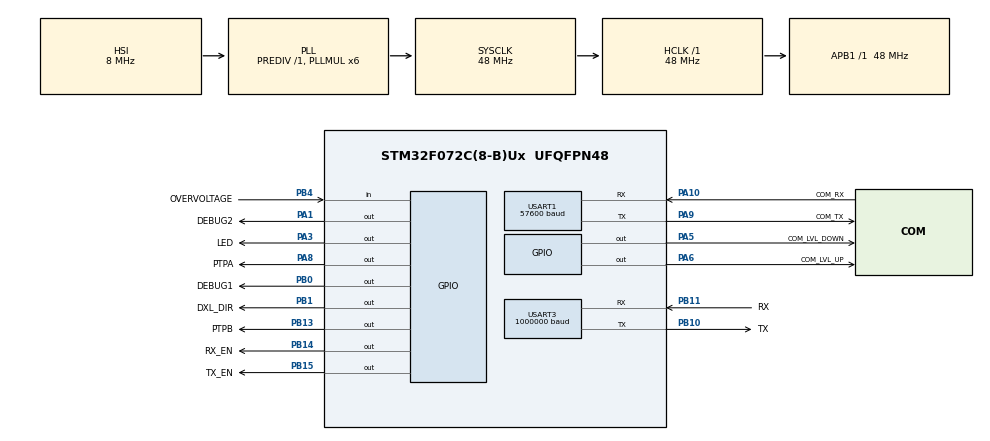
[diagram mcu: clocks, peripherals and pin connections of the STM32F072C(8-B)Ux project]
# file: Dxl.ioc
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Mcu.Family=STM32F0
Dma.USART3_RX.0.PeriphInc=DMA_PINC_DISABLE
PB13.Stacked=true
PB10.Mode=Asynchronous
PA10.GPIO_PuPd=GPIO_PULLUP
USART1.BaudRate=57600
PB14.GPIO_Label=RX_EN
VP_RTC_VS_RTC_Activate.Mode=RTC_Enabled
PA6.GPIO_Label=COM_LVL_UP
PB0.GPIO_Label=DEBUG1
PB13.GPIO_Label=PTPB
PB11.Signal=USART3_RX
PB13.Signal=SharedStack_PB13
PB15.Signal=GPIO_Output
PA5.PinState=GPIO_PIN_RESET
RCC.SYSCLKSource=RCC_SYSCLKSOURCE_PLLCLK
ProjectManager.StackSize=0x400
USART3.VirtualMode-Asynchronous=VM_ASYNC
SH.SharedStack_PB13.0=GPIO_Output+0
SH.SharedStack_PB13.1=GPIO_EXTI13
USART3.BaudRate=1000000
NVIC.USART3_4_IRQn=true\:2\:0\:true\:false\:true\:true\:true
RCC.HCLKFreq_Value=48000000
RCC.AHBFreq_Value=48000000
Dma.USART3_RX.0.MemDataAlignment=DMA_MDATAALIGN_BYTE
RCC.PLLMUL=RCC_PLL_MUL6
PA6.GPIO_PuPd=GPIO_PULLDOWN
PA5.GPIO_PuPd=GPIO_PULLUP
PB1.GPIO_Label=DXL_DIR
PA10.GPIO_Label=COM_RX
Dma.USART3_RX.0.PeriphDataAlignment=DMA_PDATAALIGN_BYTE
PA8.Signal=SharedStack_PA8
Dma.USART3_RX.0.Direction=DMA_PERIPH_TO_MEMORY
Mcu.Package=UFQFPN48
PB1.Signal=GPIO_Output
PA6.Signal=GPIO_Output
PA8.GPIO_ModeDefaultEXTI=GPIO_MODE_IT_FALLING
PA2.GPIO_Label=POWER_SENSOR
PA10.Signal=USART1_RX
Dma.USART3_RX.0.MemInc=DMA_MINC_ENABLE
RCC.APB1TimFreq_Value=48000000
SH.SharedStack_PA8.1=GPIO_EXTI8
NVIC.USART1_IRQn=true\:1\:0\:true\:false\:false\:true\:true
SH.SharedStack_PA8.0=GPIO_Output+0
Dma.Request0=USART3_RX
NVIC.EXTI4_15_IRQn=true\:0\:0\:false\:false\:true\:true\:true
PB4.Signal=GPIO_Input
PA3.Signal=GPIO_Output
Dma.USART3_RX.0.Instance=DMA1_Channel6
PA10.Mode=Asynchronous
PA9.GPIO_Label=COM_TX
PB11.GPIO_Label=RX
PA8.Stacked=true
PA6.PinState=GPIO_PIN_SET
PA9.GPIO_PuPd=GPIO_PULLUP
PB13.GPIO_ModeDefaultEXTI=GPIO_MODE_IT_FALLING
Dma.USART3_RX.0.Mode=DMA_NORMAL
USART1.VirtualMode-Asynchronous=VM_ASYNC
PA9.Mode=Asynchronous
PA8.GPIO_Label=PTPA
PB11.Mode=Asynchronous
ProjectManager.TargetToolchain=Other Toolchains (GPDSC)
PB10.GPIO_Label=TX
PA9.Signal=USART1_TX
PA1.Signal=GPIO_Output
PB10.Signal=USART3_TX
PB14.Signal=GPIO_Output
PA5.Signal=GPIO_Output
board=custom
PB13.GPIO_PuPd=GPIO_PULLUP
PB4.GPIO_Label=OVERVOLTAGE
NVIC.DMA1_Channel4_5_6_7_IRQn=true\:0\:0\:false\:false\:true\:false\:true
PB15.GPIO_Label=TX_EN
PA1.GPIO_Label=DEBUG2
Mcu.Name=STM32F072C(8-B)Ux
PA2.Signal=ADC_IN2
RCC.SYSCLKFreq_VALUE=48000000
Dma.USART3_RX.0.Priority=DMA_PRIORITY_LOW
PA5.GPIO_Label=COM_LVL_DOWN
ProjectManager.HeapSize=0x200
PA8.GPIO_PuPd=GPIO_PULLUP
RCC.APB1Freq_Value=48000000
PB0.Signal=GPIO_Output
PA3.GPIO_Label=LED

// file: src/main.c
/* USER CODE BEGIN Header */
/**
 ******************************************************************************
 * @file           : main.c
 * @brief          : Main program body
 ******************************************************************************
 * @attention
 *
 * <h2><center>&copy; Copyright (c) 2020 STMicroelectronics.
 * All rights reserved.</center></h2>
 *
 * This software component is licensed by ST under BSD 3-Clause license,
 * the "License"; You may not use this file except in compliance with the
 * License. You may obtain a copy of the License at:
 *                        opensource.org/licenses/BSD-3-Clause
 *
 ******************************************************************************
 */
/* USER CODE END Header */

#include "main.h"
#include "dma.h"
#include "rtc.h"
#include "usart.h"
#include "gpio.h"

/* USER CODE BEGIN Includes */
#include "luos_engine.h"
#include "robus_network.h"
#include "dxl.h"
/* USER CODE END Includes */

void SystemClock_Config(void);

int main(void)
{

    /* MCU Configuration--------------------------------------------------------*/

    /* Reset of all peripherals, Initializes the Flash interface and the Systick. */
    HAL_Init();

    /* Configure the system clock */
    SystemClock_Config();

    /* Initialize all configured peripherals */
    MX_GPIO_Init();
    MX_DMA_Init();
    MX_USART1_UART_Init();
    MX_USART3_UART_Init();
    MX_RTC_Init();
    /* USER CODE BEGIN 2 */
    Luos_Init();
    Robus_Init();
    Dxl_Init();
    /* USER CODE END 2 */

    /* Infinite loop */
    /* USER CODE BEGIN WHILE */
    while (1)
    {
        Luos_Loop();
        Dxl_Loop();
        /* USER CODE END WHILE */

    }
}

void SystemClock_Config(void)
{
    RCC_OscInitTypeDef RCC_OscInitStruct   = {0};
    RCC_ClkInitTypeDef RCC_ClkInitStruct   = {0};
    RCC_PeriphCLKInitTypeDef PeriphClkInit = {0};

    /** Initializes the CPU, AHB and APB busses clocks
     */
    RCC_OscInitStruct.OscillatorType      = RCC_OSCILLATORTYPE_HSI | RCC_OSCILLATORTYPE_LSI;
    RCC_OscInitStruct.HSIState            = RCC_HSI_ON;
    RCC_OscInitStruct.HSICalibrationValue = RCC_HSICALIBRATION_DEFAULT;
    RCC_OscInitStruct.LSIState            = RCC_LSI_ON;
    RCC_OscInitStruct.PLL.PLLState        = RCC_PLL_ON;
    RCC_OscInitStruct.PLL.PLLSource       = RCC_PLLSOURCE_HSI;
    RCC_OscInitStruct.PLL.PLLMUL          = RCC_PLL_MUL6;
    RCC_OscInitStruct.PLL.PREDIV          = RCC_PREDIV_DIV1;
    if (HAL_RCC_OscConfig(&RCC_OscInitStruct) != HAL_OK)
    {
        Error_Handler();
    }
    /** Initializes the CPU, AHB and APB busses clocks
     */
    RCC_ClkInitStruct.ClockType = RCC_CLOCKTYPE_HCLK | RCC_CLOCKTYPE_SYSCLK
                                  | RCC_CLOCKTYPE_PCLK1;
    RCC_ClkInitStruct.SYSCLKSource   = RCC_SYSCLKSOURCE_PLLCLK;
    RCC_ClkInitStruct.AHBCLKDivider  = RCC_SYSCLK_DIV1;
    RCC_ClkInitStruct.APB1CLKDivider = RCC_HCLK_DIV1;

    if (HAL_RCC_ClockConfig(&RCC_ClkInitStruct, FLASH_LATENCY_1) != HAL_OK)
    {
        Error_Handler();
    }
    PeriphClkInit.PeriphClockSelection = RCC_PERIPHCLK_USART1 | RCC_PERIPHCLK_RTC;
    PeriphClkInit.Usart1ClockSelection = RCC_USART1CLKSOURCE_PCLK1;
    PeriphClkInit.RTCClockSelection    = RCC_RTCCLKSOURCE_LSI;
    if (HAL_RCCEx_PeriphCLKConfig(&PeriphClkInit) != HAL_OK)
    {
        Error_Handler();
    }
}

void Error_Handler(void)
{
}

/************************ (C) COPYRIGHT STMicroelectronics *****END OF FILE****/
